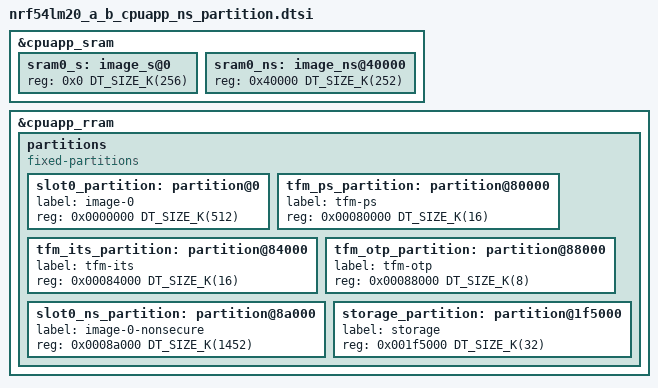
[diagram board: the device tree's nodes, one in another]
/*
 * Copyright (c) 2025 Nordic Semiconductor ASA
 *
 * SPDX-License-Identifier: Apache-2.0
 */

/*
 * Default SRAM planning when building for nRF54LM20A and nRF54LM20B with ARM TrustZone-M support
 * - Lowest 256 kB SRAM allocated to Secure image (sram0_s).
 * - Upper 252 kB SRAM allocated to Non-Secure image (sram0_ns).
 *
 * nRF54LM20A and nRF54LM20B have 512 kB of volatile memory (SRAM),
 * but only 511 kB is available to use.
 * Since TF-m requires 4kB page alignment we can only use a total of 508 kB.
 * This static layout needs to be the same with the upstream TF-M layout in the
 * header flash_layout.h of the relevant platform. Any updates in the layout
 * needs to happen both in the flash_layout.h and in this file at the same time.
 */
&cpuapp_sram {
	sram0_s: image_s@0 {
		#address-cells = <1>;
		#size-cells = <1>;
		/* Secure image memory */
		reg = <0x0 DT_SIZE_K(256)>;
		ranges = <0x0 0x0 DT_SIZE_K(256)>;
	};

	sram0_ns: image_ns@40000 {
		#address-cells = <1>;
		#size-cells = <1>;
		/* Non-Secure image memory */
		reg = <0x40000 DT_SIZE_K(252)>;
		ranges = <0x0 0x40000 DT_SIZE_K(252)>;
	};
};

&cpuapp_rram {
	/*
	 * Default NVM layout on nRF54LM20A and nRF54LM20B Application MCUs without BL2:
	 * This layout matches (by necessity) that in the TF-M repository:
	 *
	 * 0x0000_0000 Secure image primary (512 KB)
	 * 0x0008_0000 Protected Storage Area (16 KB)
	 * 0x0008_4000 Internal Trusted Storage Area (16 KB)
	 * 0x0008_8000 OTP / NV counters area (8 KB)
	 * 0x0008_A000 Non-secure image primary (1452 KB)
	 * 0x001F_5000 Non-secure storage, used when built with NRF_NS_STORAGE=ON,
	 *             otherwise unused (32 KB)
	 */
	partitions {
		compatible = "fixed-partitions";
		#address-cells = <1>;
		#size-cells = <1>;

		/* nRF54LM20A and nRF54LM20B have 2036 kB of non-volatile memory (RRAM)
		 *
		 * This static layout needs to be the same with the upstream TF-M layout in the
		 * header flash_layout.h of the relevant platform. Any updates in the layout
		 * needs to happen both in the flash_layout.h and in this file at the same time.
		 */
		slot0_partition: partition@0 {
			label = "image-0";
			reg = <0x0000000 DT_SIZE_K(512)>;
		};

		tfm_ps_partition: partition@80000 {
			label = "tfm-ps";
			reg = <0x00080000 DT_SIZE_K(16)>;
		};

		tfm_its_partition: partition@84000 {
			label = "tfm-its";
			reg = <0x00084000 DT_SIZE_K(16)>;
		};

		tfm_otp_partition: partition@88000 {
			label = "tfm-otp";
			reg = <0x00088000 DT_SIZE_K(8)>;
		};

		slot0_ns_partition: partition@8a000 {
			label = "image-0-nonsecure";
			reg = <0x0008a000 DT_SIZE_K(1452)>;
		};

		storage_partition: partition@1f5000 {
			label = "storage";
			reg = <0x001f5000 DT_SIZE_K(32)>;
		};
	};
};
